# A31G324 register map
Vendor: ABOV Semiconductor Co., Ltd.; Series: A31G324; File version: 1.0
CPU: CM0PLUS r0p1, little endian, no MPU, no FPU, VTOR, 2 interrupt priority bits
Registers are 32-bit, read-write, reset 0x0 unless marked. A register's access mark holds for its fields unless they carry their own. Offsets are from the block's base; [hi:lo] are bit positions; {n}, {i} and the like mark numbered series; 'fields as' and 'values as' point back to an identical list.

## USB (part 1 of 2)
Base 0x50000000
0x00 GOTGCTL reset 0x8D0000 — Interrupt Source Mask Register
  [26:22] MultValIdBC ro — Multi Valued ID pin (MultValIdBC)
0x04 GOTGINT reset 0x100080 — Interrupt Register
  [20] MultValIpChng — This bit when set indicates that there is a change in the value of at least one ACA pin value.
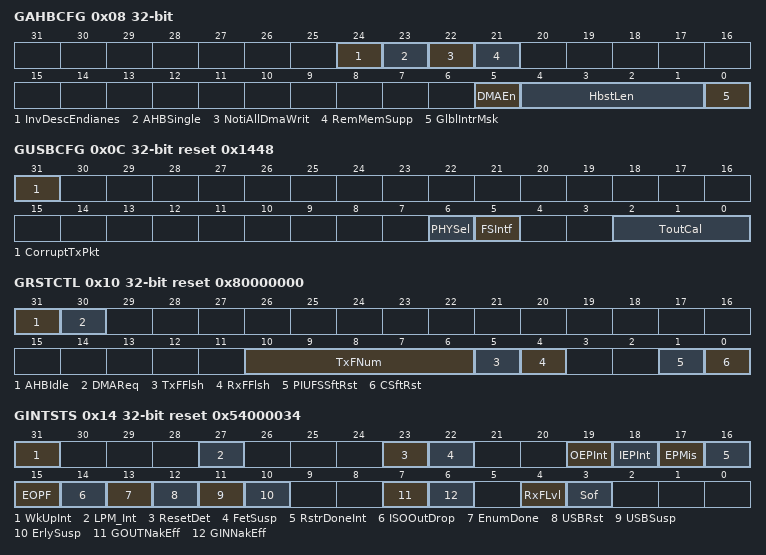
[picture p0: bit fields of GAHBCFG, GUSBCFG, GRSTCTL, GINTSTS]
0x08 GAHBCFG — AHB Configuration Register
  [24] InvDescEndianes — Invert Descriptor Endianess (InvDescEndianess)
  [23] AHBSingle — AHB Single Support (AHBSingle) This bit when programmed supports Single transfers for the remaining data in a transfer when the core is operating in DMA mode.
  [22] NotiAllDmaWrit — Notify All Dma Write Transactions (NotiAllDmaWrit) This bit is programmed to enable the System DMA Done functionality for all the DMA write Transactions corresponding to the Channel/Endpoint. This bit is valid only when GAHBCFG.RemMemSupp is set to 1.
  [21] RemMemSupp — Remote Memory Support (RemMemSupp) This bit is programmed to enable the functionality to wait for the system DMA Done Signal for the DMA Write Transfers.
  [5] DMAEn — DMA Enable (DMAEn)
  [4:1] HbstLen — Burst Length/Type (HbstLen)
  [0] GlblIntrMsk — Global Interrupt Mask (GlblIntrMsk) The application uses this bit to mask or unmask the interrupt line assertion to itself. Irrespective of this bit's setting, the interrupt status registers are updated by the controller.
0x0C GUSBCFG reset 0x1448 — USB Configuration Register
  [31] CorruptTxPkt — Corrupt Tx packet (CorruptTxPkt) This bit is for debug purposes only. Never Set this bit to 1. The application should always write 1'b0 to this bit.
  [6] PHYSel — USB 1.1 Full-Speed Serial Transceiver Select (PHYSel)
  [5] FSIntf — Full-Speed Serial Interface Select (FSIntf) The application uses this bit to select either a unidirectional or bidirectional USB 1.1 full-speed serial transceiver interface.
  [2:0] ToutCal — FS Timeout Calibration (ToutCal) The number of PHY clocks that the application programs in this field is added to the full-speed interpacket timeout duration in the core to account for any additional delays introduced by the PHY. This can be required, because the delay introduced by the PHY in generating the linestate condition can vary from one PHY to another. The USB standard timeout value for full-speed operation is 16 to 18 (inclusive) bit times. The application must program this field based on the speed of enumeration. The number of bit times added per PHY clock are as follows: Full-speed operation: -One 48-MHz PHY clock = 0.25 bit times
0x10 GRSTCTL reset 0x80000000 — Reset Register
  [31] AHBIdle — AHB Master Idle (AHBIdle) Indicates that the AHB Master State Machine is in the IDLE condition.
  [30] DMAReq — DMA Request Signal (DMAReq) Indicates that the DMA request is in progress. Used for debug
  [10:6] TxFNum — TxFIFO Number (TxFNum) This is the FIFO number that must be flushed using the TxFIFO Flush bit. This field must not be changed until the core clears the TxFIFO Flush bit.
  [5] TxFFlsh — TxFIFO Flush (TxFFlsh) This bit selectively flushes a single or all transmit FIFOs, but cannot do so If the core is in the midst of a transaction. The application must write this bit only after checking that the core is neither writing to the TxFIFO nor reading from the TxFIFO. Verify using these registers: -ReadNAK Effective Interrupt ensures the core is not reading from the FIFO -WriteGRSTCTL.AHBIdle ensures the core is not writing anything to the FIFO. Flushing is normally recommended when FIFOs are reconfigured or when switching between Shared FIFO and Dedicated Transmit FIFO operation. FIFO flushing is also recommended during device endpoint disable. The application must wait until the core clears this bit before performing any operations. This bit takes eight clocks to clear, using the slower clock of phy_clk or hclk.
  [4] RxFFlsh — RxFIFO Flush (RxFFlsh) The application can flush the entire RxFIFO using this bit, but must first ensure that the core is not in the middle of a transaction. The application must only write to this bit after checking that the controller is neither reading from the RxFIFO nor writing to the RxFIFO. The application must wait until the bit is cleared before performing any other operations. This bit requires eight clocks (slowest of PHY or AHB clock) to clear.
  [1] PIUFSSftRst — PIU FS Dedicated Controller Soft Reset (PIUFSSftRst) Resets the PIU FS Dedicated Controller All module state machines in FS Dedicated Controller of PIU are reset to the IDLE state. Used to reset the FS Dedicated controller in PIU in case of any PHY Errors like Loss of activity or Babble Error resulting in the PHY remaining in RX state for more than one frame boundary. This is a self clearing bit and core clears this bit after all the necessary logic is reset in the core.
  [0] CSftRst — Core Soft Reset (CSftRst) Resets the hclk and phy_clock domains as follows: + Clears the interrupts and all the CSR registers except the following register bits: -PCGCCTL.RstPdwnModule -PCGCCTL.GateHclk -PCGCCTL.PwrClmp -PCGCCTL.StopPPhyLPwrClkSelclk -GUSBCFG.PhyLPwrClkSel -GUSBCFG.FSIntf -GGPIO -GPWRDN -HCFG.FSLSPclkSel -DCFG.DevSpd -DCTL.SftDiscon + All module state machines + All module state machines (except the AHB Slave Unit) are reset to the IDLE state, and all the transmit FIFOs and the receive FIFO are flushed. + Any transactions on the AHB Master are terminated as soon as possible, after gracefully completing the last data phase of an AHB transfer. Any transactions on the USB are terminated immediately. + When Hibernation feature is enabled, the PMU module is not reset by the Core Soft Reset. The application can write to this bit any time it wants to reset the core. This is a self-clearing bit and the core clears this bit after all the necessary logic is reset in the core, which can take several clocks, depending on the current state of the core. Once this bit is cleared software must wait at least 3 PHY clocks before doing any access to the PHY domain (synchronization delay). Software must also must check that bit 31 of this register is 1 (AHB Master is IDLE) before starting any operation. Typically software reset is used during software development and also when you dynamically change the PHY selection bits in the USB configuration registers listed above. When you change the PHY, the corresponding clock for the PHY is selected and used in the PHY domain. Once a new clock is selected, the PHY domain has to be reset for proper operation.
0x14 GINTSTS reset 0x54000034 — Interrupt Register
  [31] WkUpInt — Resume/Remote Wakeup Detected Interrupt (WkUpInt) Wakeup Interrupt during Suspend(L2) or LPM(L1) state. + During Suspend(L2): -This interrupt is asserted only when Host Initiated Resume is detected on USB. For more information, see 'Partial Power-Down and Clock Gating Programming Model' in the Programming Guide. + During LPM(L1): -This interrupt is asserted for either Host Initiated Resume or Device Initiated Remote Wakeup on USB. For more information, see 'LPM Entry and Exit Programming Model' in the Programming Guide.
  [27] LPM_Int — LPM Transaction Received Interrupt (LPM_Int). This interrupt is asserted when the device receives an LPM transaction and responds with a non-ERRORed response. Has completed LPM transactions for the programmed number of times (GLPMCFG.RetryCnt).
  [23] ResetDet — Reset detected Interrupt (ResetDet) In Device mode, this interrupt is asserted when a reset is detected on the USB in partial power-down mode when the device is in Suspend.
  [22] FetSusp — Data Fetch Suspended (FetSusp) This interrupt is valid only in DMA mode. This interrupt indicates that the core has stopped fetching data for IN endpoints due to the unavailability of TxFIFO space or Request Queue space. This interrupt is used by the application for an endpoint mismatch algorithm. For example, after detecting an endpoint mismatch, the application: + Sets a Global non-periodic IN NAK handshake + Disables In endpoints + Flushes the FIFO + Determines the token sequence from the IN Token Sequence Learning Queue + Re-enables the endpoints + Clears the Global non-periodic IN NAK handshake If the Global non-periodic IN NAK is cleared, the core has not yet fetched data for the IN endpoint, and the IN token is received. The core generates an 'IN token received when FIFO empty' interrupt. The OTG Then sends the host a NAK response. To avoid this scenario, the application can check the GINTSTS.FetSusp interrupt, which ensures that the FIFO is full before clearing a Global NAK handshake. Alternatively, the application can mask the IN token received when FIFO empty interrupt when clearing a Global IN NAK handshake.
  [19] OEPInt — OUT Endpoints Interrupt (OEPInt) The controller sets this bit to indicate that an interrupt is pending on one of the OUT endpoints of the core (in Device mode). The application must read the Device All Endpoints Interrupt (DAINT) register to determine the exact number of the OUT endpoint on which the interrupt occurred, and then read the corresponding Device OUT Endpoint-n Interrupt (DOEPINTn) register to determine the exact cause of the interrupt. The application must clear the appropriate status bit in the corresponding DOEPINTn register to clear this bit.
  [18] IEPInt — IN Endpoints Interrupt (IEPInt) The core sets this bit to indicate that an interrupt is pending on one of the IN endpoints of the core (in Device mode). The application must read the Device All Endpoints Interrupt (DAINT) register to determine the exact number of the IN endpoint on Device IN Endpoint-n Interrupt (DIEPINTn) register to determine the exact cause of the interrupt. The application must clear the appropriate status bit in the corresponding DIEPINTn register to clear this bit.
  [17] EPMis — Endpoint Mismatch Interrupt (EPMis) Note: This interrupt is valid only in shared FIFO operation. Indicates that an IN token has been received for a non-periodic endpoint, but the data for another endpoint is present in the top of the Non-periodic Transmit FIFO and the IN endpoint mismatch count programmed by the application has expired.
  [16] RstrDoneInt — Restore Done Interrupt (RstrDoneInt) The controller sets this bit to indicate that the restore command after Hibernation was completed by the core. The controller continues from Suspended state into the mode dictated by PCGCCTL.RestoreMode field.
  [15] EOPF — End of Periodic Frame Interrupt (EOPF) Indicates that the period specified in the Periodic Frame Interval field of the Device Configuration register (DCFG.PerFrInt) has been reached in the current microframe.
  [14] ISOOutDrop — Isochronous OUT Packet Dropped Interrupt (ISOOutDrop) The controller sets this bit when it fails to write an isochronous OUT packet into the RxFIFO because the RxFIFO does not have enough space to accommodate a maximum packet size packet for the isochronous OUT endpoint.
  [13] EnumDone — Mode: Device only Enumeration Done (EnumDone) The core sets this bit to indicate that speed enumeration is complete. The application must read the Device Status (DSTS) register to obtain the enumerated speed.
  [12] USBRst — USB Reset (USBRst) The controller sets this bit to indicate that a reset is detected on the USB.
  [11] USBSusp — USB Suspend (USBSusp) The controller sets this bit to indicate that a suspend was detected on the USB. The controller enters the Suspended state when there is no activity on the linestate signal for an extended period of time.
  [10] ErlySusp — Early Suspend (ErlySusp) The controller sets this bit to indicate that an Idle state has been detected on the USB for 3 ms.
  [7] GOUTNakEff — Global OUT NAK Effective (GOUTNakEff) Indicates that the Set Global OUT NAK bit in the Device Control register (DCTL.SGOUTNak), Set by the application, has taken effect in the core. This bit can be cleared by writing the Clear Global OUT NAK bit in the Device Control register (DCTL.CGOUTNak).
  [6] GINNakEff — Global IN Non-periodic NAK Effective (GINNakEff) Indicates that the Set Global Non-periodic IN NAK bit in the Device Control register (DCTL.SGNPInNak) set by the application, has taken effect in the core. That is, the core has sampled the Global IN NAK bit Set by the application. This bit can be cleared by clearing the Clear Global Non-periodic IN NAK bit in the Device Control register (DCTL.CGNPInNak). This interrupt does not necessarily mean that a NAK handshake is sent out on the USB. The STALL bit takes precedence over the NAK bit.
  [4] RxFLvl — RxFIFO Non-Empty (RxFLvl) Indicates that there is at least one packet pending to be read from the RxFIFO.
  [3] Sof — Start of (micro)Frame (Sof) In Device mode, the controller sets this bit to indicate that an SOF token has been received on the USB. The application can read the Device Status register to get the current (micro)Frame number. This interrupt is seen only when the core is operating at FS. This bit can be set only by the core and the application must write 1 to clear it. Note: This register may return 1'b1 if read immediately after power-on reset. If the register bit reads 1'b1 immediately after power-on reset, it does not indicate that an SOF has been received. The read value of this interrupt is valid only after a valid connection between host and device is established. If the bit is set after power on reset the application can clear the bit.
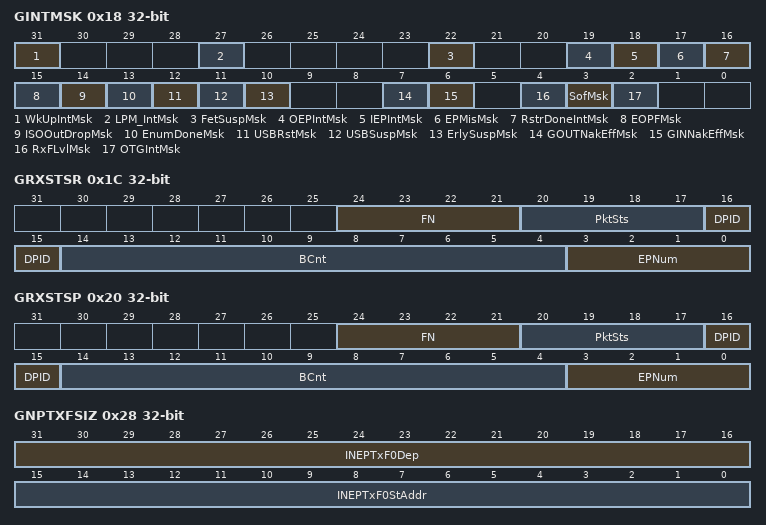
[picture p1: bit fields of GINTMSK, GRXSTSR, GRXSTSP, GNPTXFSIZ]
0x18 GINTMSK — Interrupt Mask Register
  [31] WkUpIntMsk — Resume/Remote Wakeup Detected Interrupt Mask (WkUpIntMsk) The WakeUp bit is used for LPM state wake up in a way similar to that of wake up in suspend state.
  [27] LPM_IntMsk — LPM Transaction Received Interrupt (LPM_Int) LPM Transaction received interrupt Mask
  [22] FetSuspMsk — Data Fetch Suspended Mask (FetSuspMsk)
  [19] OEPIntMsk — Mode: Device only OUT Endpoints Interrupt Mask (OEPIntMsk)
  [18] IEPIntMsk — Mode: Device only IN Endpoints Interrupt Mask (IEPIntMsk)
  [17] EPMisMsk — Mode: Device only Endpoint Mismatch Interrupt Mask (EPMisMsk)
  [16] RstrDoneIntMsk — Restore Done Interrupt Mask (RstrDoneIntMsk)
  [15] EOPFMsk — Mode: Device only End of Periodic Frame Interrupt Mask (EOPFMsk)
  [14] ISOOutDropMsk — Mode: Device only Isochronous OUT Packet Dropped Interrupt Mask (ISOOutDropMsk)
  [13] EnumDoneMsk — Mode: Device only Enumeration Done Mask (EnumDoneMsk)
  [12] USBRstMsk — Mode: Device only USB Reset Mask (USBRstMsk)
  [11] USBSuspMsk — Mode: Device only USB Suspend Mask (USBSuspMsk)
  [10] ErlySuspMsk — Mode: Device only Early Suspend Mask (ErlySuspMsk)
  [7] GOUTNakEffMsk — Mode: Device only Global OUT NAK Effective Mask (GOUTNakEffMsk)
  [6] GINNakEffMsk — Mode: Device only, Global Non-periodic IN NAK Effective Mask (GINNakEffMsk)
  [4] RxFLvlMsk — Receive FIFO Non-Empty Mask (RxFLvlMsk)
  [3] SofMsk — Start of (micro)Frame Mask (SofMsk)
  [2] OTGIntMsk — OTG Interrupt Mask (OTGIntMsk)
0x1C GRXSTSR — Receive Status Debug Read Register
  [24:21] FN ro — Mode: Device only Frame Number (FN) This is the least significant 4 bits of the (micro)Frame number in which the packet is received on the USB. This field is supported only when isochronous OUT endpoints are supported.
  [20:17] PktSts ro — Packet Status (PktSts) Indicates the status of the received packet
  [16:15] DPID ro — Data PID (DPID) Indicates the Data PID of the received OUT data packet
  [14:4] BCnt ro — Byte Count (BCnt) Indicates the byte count of the received data packet.
  [3:0] EPNum ro — Endpoint Number (EPNum) Indicates the endpoint number to which the current received packet belongs.
0x20 GRXSTSP — Receive Status Read/Pop Register
  fields as GRXSTSR
0x24 GRXFSIZ — Receive FIFO Size Register
  [10:0] RxFDep — RxFIFO Depth (RxFDep) This value is in terms of 32-bit words. + Minimum value is 16 + Maximum value is 32,768 The power-on reset value of this register is specified as the Largest Rx Data FIFO Depth during configuration. You can write a new value in this field. Programmed values must not exceed the power-on value.
0x28 GNPTXFSIZ — Non-periodic Transmit FIFO Size Register
  [31:16] INEPTxF0Dep — IN Endpoint TxFIFO 0 Depth (INEPTxF0Dep) This value is in terms of 32-bit words. + Minimum value is 16 + Maximum value is 32,768 The application can write a new value in this field. Programmed values must not exceed the power-on value set in coreConsultant. The power-on reset value of this field is specified during coreConsultant configuration as Largest IN Endpoint FIFO 0 Depth (parameter OTG_TX_DINEP_DFIFO_DEPTH_0).
  [15:0] INEPTxF0StAddr — IN Endpoint FIFO0 Transmit RAM Start Address(INEPTxF0StAddr) This field contains the memory start address for IN Endpoint Transmit FIFO# 0. Programmed values must not exceed the power-on value.
0x40 GSNPSID — Synopsys ID Register
  [31:0] SynopsysID ro — Release number of the controller being used currently.
0x44 GHWCFG1 — User HW Config1 Register
  [31:0] EpDir ro — This 32-bit field uses two bits per endpoint to determine the endpoint direction.
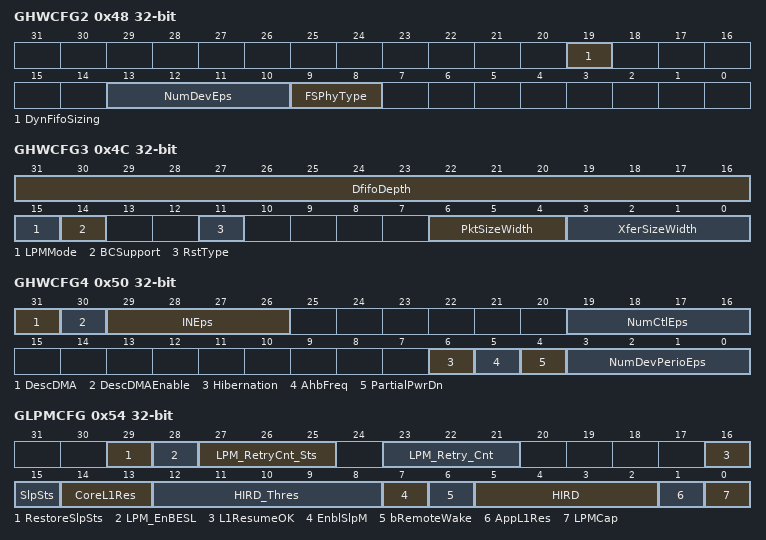
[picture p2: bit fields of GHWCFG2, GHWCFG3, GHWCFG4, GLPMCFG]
0x48 GHWCFG2 — User HW Config2 Register
  [19] DynFifoSizing ro — Dynamic FIFO Sizing Enabled (DynFifoSizing)
  [13:10] NumDevEps ro — Number of Device Endpoints (NumDevEps) Indicates the number of device endpoints supported by the core. The range of this field is 0-4.
  [9:8] FSPhyType ro — Full-Speed PHY Interface Type (FSPhyType)
0x4C GHWCFG3 — User HW Config3 Register
  [31:16] DfifoDepth ro — DFIFO Depth (DfifoDepth - EP_LOC_CNT) This value is in terms of 32-bit words.
  [15] LPMMode ro — LPM mode specified for Mode of Operation.
  [14] BCSupport ro — This bit indicates the controller support for Battery Charger.
  [11] RstType ro — Reset Style for Clocked always Blocks in RTL (RstType)
  [6:4] PktSizeWidth ro — Width of Packet Size Counters (PktSizeWidth)
  [3:0] XferSizeWidth ro — Width of Transfer Size Counters (XferSizeWidth)
0x50 GHWCFG4 — User HW Config4 Register
  [31] DescDMA ro — Scatter/Gather DMA configuration + 1'b0: Non Dynamic configuration + 1'b1: Dynamic configuration
  [30] DescDMAEnable ro — Scatter/Gather DMA configuration + 1'b0: Non-Scatter/Gather DMA configuration + 1'b1: Scatter/Gather DMA configuration
  [29:26] INEps ro — Number of Device Mode IN Endpoints Including Control Endpoints (INEps)
  [19:16] NumCtlEps ro — Number of Device Mode Control Endpoints in Addition to Endpoint 0 (NumCtlEps)
  [6] Hibernation ro — Enable Hibernation (Hibernation)
  [5] AhbFreq ro — Minimum AHB Frequency Less Than 60 MHz (AhbFreq)
  [4] PartialPwrDn ro — Enable Partial Power Down (PartialPwrDn)
  [3:0] NumDevPerioEps ro — Number of Device Mode Periodic IN Endpoints (NumDevPerioEps)
0x54 GLPMCFG — LPM Config Register
  [29] RestoreSlpSts — LPM Restore Sleep Status (LPM_RestoreSlpSts) When the application power gates the core (Partial Power Down / Hibernation) the application needs to program this bit to restore the LPM status in the core. The application needs to program this bit, during restore process, based on whether it had decided to go into Shallow Sleep (Clock Gating Only) or Deep Sleep (Power Gating) based on the BESL value received from the Host
  [28] LPM_EnBESL — LPM Enable BESL (LPM_EnBESL)
  [27:25] LPM_RetryCnt_Sts — LPM Retry Count Status (LPM_RetryCnt_Sts) Number of LPM Host Retries still remaining to be transmitted for the current LPM sequence.
  [23:21] LPM_Retry_Cnt — LPM Retry Count (LPM_Retry_Cnt) Number of additional LPM retries that the HOST would perform if the Device Response was an ERROR until a valid device response is received (STALL/NYET/ACK).
  [16] L1ResumeOK — Sleep State Resume OK (L1ResumeOK) Indicates that the application or host can start resume from Sleep state. This bit is valid in LPM sleep (L1) state. It is set in sleep mode after a delay of 50 micro sec (TL1Residency). The bit is reset when SlpSts is 0.
  [15] SlpSts — Port Sleep Status (SlpSts) This bit is set as long as a Sleep condition is present on the USB bus. The core enters the Sleep state when an ACK response is sent to an LPM transaction and the expiry of timer TL1TokenRetry.
  [14:13] CoreL1Res — LPM response (CoreL1Res) The response of the core to LPM transaction received is reflected in these two bits.
  [12:8] HIRD_Thres — BESL/HIRD Threshold (HIRD_Thres)
  [7] EnblSlpM — Enable utmi_sleep_n (EnblSlpM) The application uses this bit to control utmi_sleep_n assertion to the PHY in the L1 state.
  [6] bRemoteWake — RemoteWakeEnable (bRemoteWake) This field is read only. It is updated with the Received LPM Token bRemoteWake bmAttribute when an ACK/NYET/STALL response is sent to an LPM transaction.
  [5:2] HIRD — Host-Initiated Resume Duration (HIRD)
  [1] AppL1Res — LPM response programmed by application (AppL1Res)
  [0] LPMCap — The application uses this bit to control the controller LPM capabilities. If the core operates as a non-LPM-capable host, it cannot request the connected device/hub to activate LPM mode. If the core operates as a non-LPM-capable device, it cannot respond to any LPM transactions.
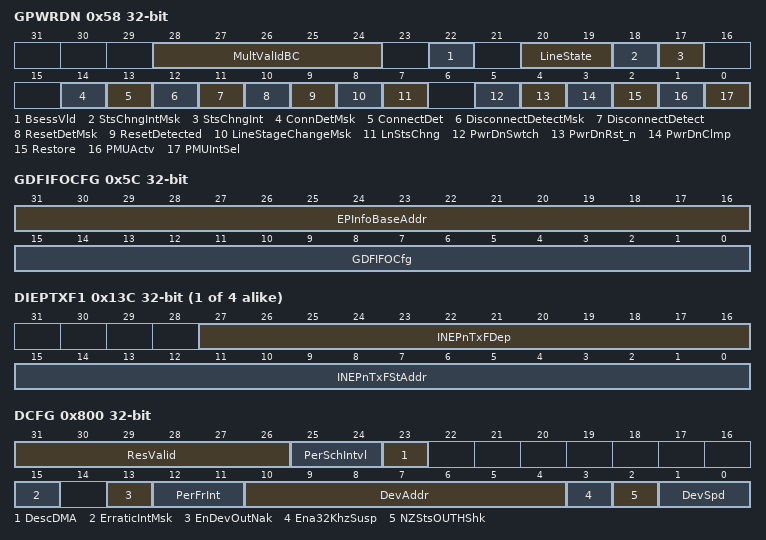
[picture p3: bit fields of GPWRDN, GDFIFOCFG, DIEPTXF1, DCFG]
0x58 GPWRDN — Global Power Down register
  [28:24] MultValIdBC ro — MultValIdBC Battery Charger ACA inputs
  [22] BsessVld ro — B Session Valid (BsessVld) This field reflects the B session valid status signal from the PHY.
  [20:19] LineState ro — LineState This field indicates the current linestate on USB as seen by the PMU module.
  [18] StsChngIntMsk — StsChngIntMsk Mask for StsChng Interrupt
  [17] StsChngInt — Status Change Interrupt (StsChngInt) This field indicates a status change in either the IDDIG or BsessVld signal.
  [14] ConnDetMsk — ConnDetMsk Mask for ConnectDet interrupt
  [13] ConnectDet — ConnectDet This field indicates that a new connect has been detected
  [12] DisconnectDetectMsk — DisconnectDetectMsk Mask For DisconnectDetect Interrupt
  [11] DisconnectDetect — DisconnectDetect This field indicates that Disconnect has been detected by the PMU. This field generates an interrupt. After detecting disconnect during hibernation the application must not restore the core, but instead start the initialization process.
  [10] ResetDetMsk — ResetDetMsk Mask for ResetDetected interrupt
  [9] ResetDetected — ResetDetected This field indicates that Reset has been detected by the PMU module. This field generates an interrupt.
  [8] LineStageChangeMsk — LineStageChangeMsk Mask for LineStateChange interrupt.
  [7] LnStsChng — Line State Change (LnStsChng) This interrupt is asserted when there is a Linestate Change detected by the PMU. The application should read GPWRDN.Linestate to determine the current linestate on USB.
  [5] PwrDnSwtch — Power Down Switch (PwrDnSwtch) This bit indicates to the controller whether the VDD switch is in ON/OFF state.
  [4] PwrDnRst_n — Power Down ResetN (PwrDnRst_n) The application must program this bit to reset the core during the Hibernation exit process.
  [3] PwrDnClmp — Power Down Clamp (PwrDnClmp) The application must program this bit to enable or disable the clamps to all the outputs of the core module to prevent the corruption of other active logic.
  [2] Restore — Restore The application should program this bit to enable or disable restore mode from the PMU module.
  [1] PMUActv — PMU Active (PMUActv) This is bit is to enable or disable the PMU logic.
  [0] PMUIntSel — PMU Interrupt Select (PMUIntSel) A write to this bit with 1'b1 enables the PMU to generate interrupts to the application. During this state all interrupts from the DWC_usb11_device_core module are blocked to the application. Note: This bit must be set to 1'b1 before the core is put into hibernation.
0x5C GDFIFOCFG — Global DFIFO Configuration Register
  [31:16] EPInfoBaseAddr — EPInfoBaseAddr This field provides the start address of the EP info controller
  [15:0] GDFIFOCfg — GDFIFOCfg This field is for dynamic programming of the DFIFO Size. This value takes effect only when the application programs a non zero value to this register. The value programmed must conform to the guidelines described in 'FIFO RAM Allocation'. The core does not have any corrective logic if the FIFO sizes are programmed incorrectly.
{0x138+4i} DIEPTXF{i} (i=1..4) — Device IN Endpoint Transmit FIFO Size Register i
  [27:16] INEPnTxFDep — IN Endpoint TxFIFO Depth (INEPnTxFDep) This value is in terms of 32-bit words.
  [15:0] INEPnTxFStAddr — IN Endpoint FIFOn Transmit RAM Start Address (INEPnTxFStAddr) This field contains the memory start address for IN endpoint Transmit FIFOn (0<n< = 15). The power-on reset value of this register is specified as the Largest Rx Data FIFO Depth. Programmed values must not exceed the power-on value.
0x800 DCFG — Device Configuration Register
  [31:26] ResValid — Resume Validation Period (ResValid) This field is effective only when DCFG.Ena32KhzSusp is set. It will control the resume period when the core resumes from suspend. The core counts for ResValid number of clock cycles to detect a valid resume when this is set
  [25:24] PerSchIntvl — Periodic Scheduling Interval (PerSchIntvl) PerSchIntvl must be programmed for Scatter/Gather DMA mode. This field specifies the amount of time the Internal DMA engine must allocate for fetching periodic IN endpoint data. Based on the number of periodic endpoints, this value must be specified as 25,50 or 75% of (micro)frame.
  [23] DescDMA — Enable Scatter/gather DMA in device mode (DescDMA). When the Scatter/Gather DMA option selected during configuration of the RTL, the application can Set this bit during initialization to enable the Scatter/Gather DMA operation.
  [15] ErraticIntMsk — Erratic Error Interrupt Mask
  [13] EnDevOutNak — Enable Device OUT NAK (EnDevOutNak) This bit enables setting NAK for Bulk OUT endpoints after the transfer is completed for Device mode Descriptor DMA
  [12:11] PerFrInt — Periodic Frame Interval (PerFrInt) Indicates the time within a (micro)frame at which the application must be notified using the End Of Periodic Frame Interrupt. This can be used to determine If all the isochronous traffic for that (micro)frame is complete.
  [10:4] DevAddr — Device Address (DevAddr) The application must program this field after every SetAddress control command.
  [3] Ena32KhzSusp — Enable 32 KHz Suspend mode (Ena32KhzSusp) As FS PHY interface is chosen, when this bit is set, the core expects that the PHY clock during Suspend is switched from 48 MHz to 32 KHz.
  [2] NZStsOUTHShk — Non-Zero-Length Status OUT Handshake (NZStsOUTHShk) The application can use this field to select the handshake the core sends on receiving a nonzero-length data packet during the OUT transaction of a control transfer's Status stage.
  [1:0] DevSpd — Device Speed (DevSpd) Indicates the speed at which the application requires the core to enumerate, or the maximum speed the application can support. However, the actual bus speed is determined only after the connect sequence is completed, and is based on the speed of the USB host to which the core is connected.
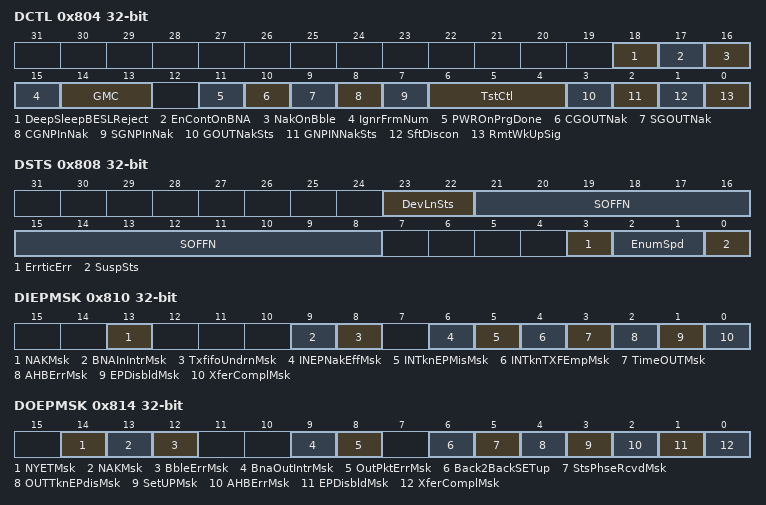
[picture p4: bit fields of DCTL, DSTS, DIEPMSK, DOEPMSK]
0x804 DCTL — Device Control Register
  [18] DeepSleepBESLReject — DeepSleepBESLReject When enabled Core rejects LPM request with HIRD value greater than HIRD threshold programmed. NYET response is sent for LPM tokens with HIRD value greater than HIRD threshold. By default, the Deep Sleep BESL Reject feature is disabled.
  [17] EnContOnBNA — Enable Continue on BNA (EnContOnBNA) This bit enables the core to continue on BNA for Bulk OUT endpoints. With this feature enabled, when a Bulk OUT endpoint receives a BNA interrupt the core starts processing the descriptor that caused the BNA interrupt after the endpoint re-enables the endpoint.
  [16] NakOnBble — NAK on Babble Error (NakOnBble) Set NAK automatically on babble (NakOnBble). The core sets NAK automatically for the endpoint on which babble is received.
  [15] IgnrFrmNum — Ignore Frame number for Isochronous End points (IgnrFrmNum) Do not program IgnrFrmNum bit to 1'b1 when the core is operating in threshold mode. When this bit is enabled, there must be only one packet per descriptor.
  [14:13] GMC — Global Multi Count (GMC) GMC must be programmed only once after initialization. This field indicates the number of packets to be serviced for that end point before moving to the next end point. It is only for non-periodic endpoints.
  [11] PWROnPrgDone — Power-On Programming Done (PWROnPrgDone) The application uses this bit to indicate that register programming is completed after a wake-up from Power Down mode.
  [10] CGOUTNak — Clear Global OUT NAK (CGOUTNak) A write to this field clears the Global OUT NAK.
  [9] SGOUTNak — Set Global OUT NAK (SGOUTNak) A write to this field sets the Global OUT NAK. The application uses this bit to send a NAK handshake on all OUT endpoints. The application must set the this bit only after making sure that the Global OUT NAK Effective bit in the Core Interrupt Register (GINTSTS.GOUTNakEff) is cleared.
  [8] CGNPInNak — Clear Global Non-periodic IN NAK (CGNPInNak) A write to this field clears the Global Non-periodic IN NAK.
  [7] SGNPInNak — Set Global Non-periodic IN NAK (SGNPInNak) A write to this field sets the Global Non-periodic IN NAK.The application uses this bit to send a NAK handshake on all non-periodic IN endpoints. The core can also Set this bit when a timeout condition is detected on a non-periodic endpoint in shared FIFO operation. The application must Set this bit only after making sure that the Global IN NAK Effective bit in the Core Interrupt Register (GINTSTS.GINNakEff) is cleared
  [6:4] TstCtl — Test Control (TstCtl)
  [3] GOUTNakSts ro — Global OUT NAK Status (GOUTNakSts)
  [2] GNPINNakSts ro — Global Non-periodic IN NAK Status (GNPINNakSts)
  [1] SftDiscon — Soft Disconnect (SftDiscon) The application uses this bit to signal the controller to do a soft disconnect. As long as this bit is Set, the host does not see that the device is connected, and the device does not receive signals on the USB. The core stays in the disconnected state until the application clears this bit.
  [0] RmtWkUpSig — Remote Wakeup Signaling (RmtWkUpSig) When the application sets this bit, the core initiates remote signaling to wake up the USB host. The application must Set this bit to instruct the core to exit the Suspend state. As specified in the USB 2.0 specification, the application must clear this bit 1-15 ms after setting it. Remote Wakeup Signaling (RmtWkUpSig) When LPM is enabled, In L1 state the behavior of this bit is as follows: When the application sets this bit, the core initiates L1 remote signaling to wake up the USB host. The application must set this bit to instruct the core to exit the Sleep state. As specified in the LPM specification, the hardware will automatically clear this bit after a time of 50 micro sec (TL1DevDrvResume) after set by application. Application should not set this bit when GLPMCFG bRemoteWake from the previous LPM transaction was zero.
0x808 DSTS ro — Device Status Register
  [23:22] DevLnSts rw — Device Line Status (DevLnSts) Indicates the current logic level USB data lines
  [21:8] SOFFN rw — Number of the Received SOF (SOFFN) Note: This register may return a non-zero value if read immediately after power-on reset. In case the register bit reads non-zero immediately after power-on reset, it does not indicate that SOF has been received from the host. The read value of this interrupt is valid only after a valid connection between host and device is established.
  [3] ErrticErr rw — Erratic Error (ErrticErr) The core sets this bit to report any erratic errors due to PHY error). Because of erratic errors, the controller goes into Suspended state and an interrupt is generated to the application with Early Suspend bit of the Core Interrupt register (GINTSTS.ErlySusp). If the early suspend is asserted due to an erratic error, the application can only perform a soft disconnect recover.
  [2:1] EnumSpd rw — Enumerated Speed (EnumSpd) Indicates the speed at which the controller has come up after speed detection through a chirp sequence.
  [0] SuspSts rw — Suspend Status (SuspSts) In Device mode, this bit is set as long as a Suspend condition is detected on the USB. The core enters the Suspended state when there is no activity on the phy_line_state_i signal for an extended period of time. The core comes out of the suspend
0x810 DIEPMSK — Device IN Endpoint Common Interrupt Mask Register
  [13] NAKMsk — NAK interrupt Mask (NAKMsk)
  [9] BNAInIntrMsk — BNA interrupt Mask (BNAInIntrMsk)
  [8] TxfifoUndrnMsk — Fifo Underrun Mask (TxfifoUndrnMsk)
  [6] INEPNakEffMsk — IN Endpoint NAK Effective Mask (INEPNakEffMsk)
  [5] INTknEPMisMsk — IN Token received with EP Mismatch Mask (INTknEPMisMsk)
  [4] INTknTXFEmpMsk — IN Token Received When TxFIFO Empty Mask (INTknTXFEmpMsk)
  [3] TimeOUTMsk — Timeout Condition Mask (TimeOUTMsk) (Non-isochronous endpoints)
  [2] AHBErrMsk — AHB Error Mask (AHBErrMsk)
  [1] EPDisbldMsk — Endpoint Disabled Interrupt Mask (EPDisbldMsk)
  [0] XferComplMsk — Transfer Completed Interrupt Mask (XferComplMsk)
0x814 DOEPMSK — Device OUT Endpoint Common Interrupt Mask Register
  [14] NYETMsk — NYET interrupt Mask (NYETMsk)
  [13] NAKMsk — NAK interrupt Mask (NAKMsk)
  [12] BbleErrMsk — Babble Error interrupt Mask (BbleErrMsk)
  [9] BnaOutIntrMsk — BNA interrupt Mask (BnaOutIntrMsk)
  [8] OutPktErrMsk — OUT Packet Error Mask (OutPktErrMsk)
  [6] Back2BackSETup — Back-to-Back SETUP Packets Received Mask (Back2BackSETup) Applies to control OUT endpoints only.
  [5] StsPhseRcvdMsk — Status Phase Received Mask (StsPhseRcvdMsk) Applies to control OUT endpoints only.
  [4] OUTTknEPdisMsk — OUT Token Received when Endpoint Disabled Mask (OUTTknEPdisMsk) Applies to control OUT endpoints only.
  [3] SetUPMsk — SETUP Phase Done Mask (SetUPMsk) Applies to control endpoints only.
  [2] AHBErrMsk — AHB Error (AHBErrMsk)
  [1] EPDisbldMsk — Endpoint Disabled Interrupt Mask (EPDisbldMsk)
  [0] XferComplMsk — Transfer Completed Interrupt Mask (XferComplMsk)
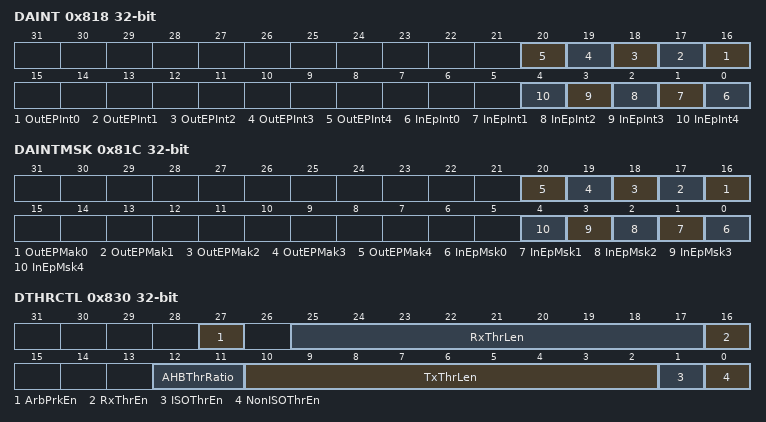
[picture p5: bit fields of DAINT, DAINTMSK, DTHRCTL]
0x818 DAINT ro — Device All Endpoints Interrupt Register
  [n+16] OutEPInt{n} rw (n=0..4) — OUT Endpoint {n} Interrupt Bit
  [n] InEpInt{n} rw (n=0..4) — IN Endpoint {n} Interrupt Bit
0x81C DAINTMSK — Device All Endpoints Interrupt Mask Register
  [n+16] OutEPMak{n} (n=0..4) — OUT Endpoint {n} Interrupt mask Bit
  [n] InEpMsk{n} (n=0..4) — IN Endpoint {n} Interrupt mask Bit
0x830 DTHRCTL — Device Threshold Control Register
  [27] ArbPrkEn — Arbiter Parking Enable (ArbPrkEn) This bit controls internal DMA arbiter parking for IN endpoints. When thresholding is enabled and this bit is Set to one, Then the arbiter parks on the IN endpoint for which there is a token received on the USB. This is done to avoid getting into underrun conditions. By Default the parking is enabled.
  [25:17] RxThrLen — Receive Threshold Length (RxThrLen) This field specifies Receive thresholding size in DWORDS. This field also specifies the amount of data received on the USB before the core can start transmitting on the AHB. The threshold length has to be at least eight DWORDS. The recommended value for ThrLen is to be the same as the programmed AHB Burst Length (GAHBCFG.HbstLen).
  [16] RxThrEn — Receive Threshold Enable (RxThrEn) When this bit is set, the core enables thresholding in the receive direction. Note: We recommends that you do not enable RxThrEn, because it may cause issues in the RxFIFO especially during error conditions such as RxError and Babble.
  [12:11] AHBThrRatio — AHB Threshold Ratio (AHBThrRatio) These bits define the ratio between the AHB threshold and the MAC threshold for the transmit path only. The AHB threshold always remains less than or equal to the USB threshold, because this does not increase overhead. Both the AHB and the MAC threshold must be DWORD-aligned. The application needs to program TxThrLen and the AHBThrRatio to make the AHB Threshold value DWORD aligned. If the AHB threshold value is not DWORD aligned, the core might not behave correctly. When programming the TxThrLen and AHBThrRatio, the application must ensure that the minimum AHB threshold value does not go below 8 DWORDS to meet the USB turnaround time requirements.
  [10:2] TxThrLen — Transmit Threshold Length (TxThrLen) This field specifies Transmit thresholding size in DWORDS. This also forms the MAC threshold and specifies the amount of data in bytes to be in the corresponding endpoint transmit FIFO, before the core can start transmit on the USB. The threshold length has to be at least eight DWORDS when the value of AHBThrRatio is 2'h00. In case the AHBThrRatio is non zero the application needs to ensure that the AHB Threshold value does not go below the recommended eight DWORD. This field controls both isochronous and non-isochronous IN endpoint thresholds. The recommended value for ThrLen is to be the same as the programmed AHB Burst Length (GAHBCFG.HbstLen).
  [1] ISOThrEn — ISO IN Endpoints Threshold Enable. (ISOThrEn) When this bit is Set, the core enables thresholding for isochronous IN endpoints.
  [0] NonISOThrEn — Non-ISO IN Endpoints Threshold Enable. (NonISOThrEn) When this bit is Set, the core enables thresholding for Non Isochronous IN endpoints.
